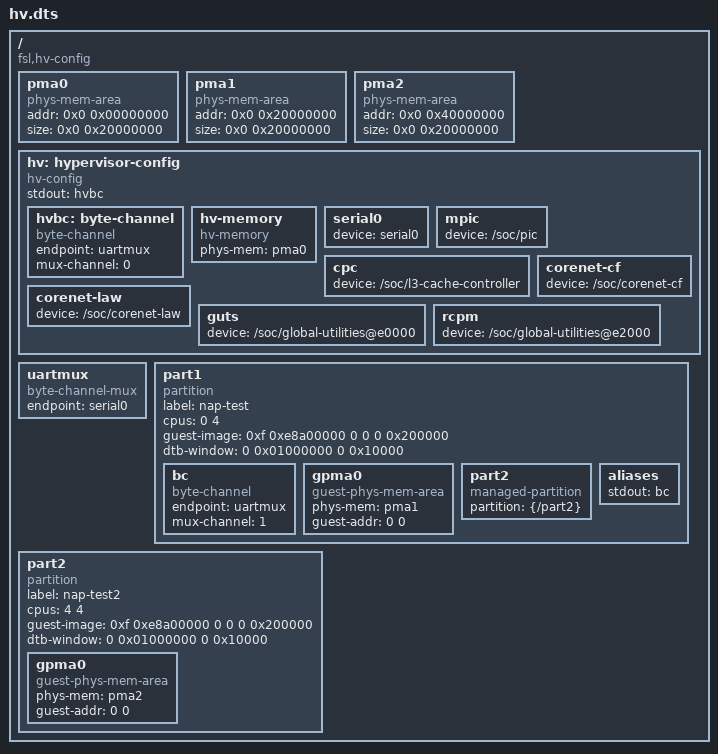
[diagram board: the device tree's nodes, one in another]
/*
 * Copyright (C) 2010 Freescale Semiconductor, Inc.
 *
 * Redistribution and use in source and binary forms, with or without
 * modification, are permitted provided that the following conditions
 * are met:
 * 1. Redistributions of source code must retain the above copyright
 *    notice, this list of conditions and the following disclaimer.
 * 2. Redistributions in binary form must reproduce the above copyright
 *    notice, this list of conditions and the following disclaimer in the
 *    documentation and/or other materials provided with the distribution.
 *
 * THIS SOFTWARE IS PROVIDED BY THE AUTHOR "AS IS" AND ANY EXPRESS OR
 * IMPLIED WARRANTIES, INCLUDING, BUT NOT LIMITED TO, THE IMPLIED WARRANTIES
 * OF MERCHANTABILITY AND FITNESS FOR A PARTICULAR PURPOSE ARE DISCLAIMED.  IN
 * NO EVENT SHALL THE AUTHOR BE LIABLE FOR ANY DIRECT, INDIRECT, INCIDENTAL,
 * SPECIAL, EXEMPLARY, OR CONSEQUENTIAL DAMAGES (INCLUDING, BUT NOT LIMITED
 * TO, PROCUREMENT OF SUBSTITUTE GOODS OR SERVICES; LOSS OF USE, DATA, OR
 * PROFITS; OR BUSINESS INTERRUPTION) HOWEVER CAUSED AND ON ANY THEORY OF
 * LIABILITY, WHETHER IN CONTRACT, STRICT LIABILITY, OR TORT (INCLUDING
 * NEGLIGENCE OR OTHERWISE) ARISING IN ANY WAY OUT OF THE USE OF THIS
 * SOFTWARE, EVEN IF ADVISED OF THE POSSIBILITY OF SUCH DAMAGE.
 */

/dts-v1/;

/ {
	compatible = "fsl,hv-config";

	// =====================================================
	// Physical Memory Areas
	// =====================================================
	pma0:pma0 {
		compatible = "phys-mem-area";
		addr = <0x0 0x00000000>;
		size = <0x0 0x20000000>;  // 512MB
	};

	pma1:pma1 {
		compatible = "phys-mem-area";
		addr = <0x0 0x20000000>;
		size = <0x0 0x20000000>;  // 512MB
	};

	pma2:pma2 {
		compatible = "phys-mem-area";
		addr = <0x0 0x40000000>;
		size = <0x0 0x20000000>;  // 512MB
	};

	// =====================================================
	// Hypervisor Config
	// =====================================================
	hv:hypervisor-config {
		compatible = "hv-config";
		stdout = <&hvbc>;

		hvbc: byte-channel {
			compatible = "byte-channel";
			endpoint = <&uartmux>;
			mux-channel = <0>;
		};

		hv-memory {
			compatible = "hv-memory";
			phys-mem = <&pma0>;
		};

		serial0:serial0 {
			device = "serial0";
		};

		mpic {
			device = "/soc/pic";
		};

		cpc {
			device = "/soc/l3-cache-controller";
		};

		corenet-law {
			device = "/soc/corenet-law";
		};

		corenet-cf {
			device = "/soc/corenet-cf";
		};

		guts {
			device = "/soc/global-utilities@e0000";
		};

		rcpm {
			device = "/soc/global-utilities@e2000";
		};
	};

	uartmux: uartmux {
		compatible = "byte-channel-mux";
		endpoint = <&serial0>;
	};

	// =====================================================
	// Partition 1
	// =====================================================
	part1 {
		compatible = "partition";
		label = "nap-test";
		cpus = <0 4>;
		guest-image = <0xf 0xe8a00000 0 0 0 0x200000>;
		dtb-window = <0 0x01000000 0 0x10000>;

		bc: bc {
			compatible = "byte-channel";
			endpoint = <&uartmux>;
			mux-channel = <1>;
		};

		gpma0 {
			compatible = "guest-phys-mem-area";
			phys-mem = <&pma1>;
			guest-addr = <0 0>;
		};

		part2 {
			compatible = "managed-partition";
			partition = <&{/part2}>;
		};

		aliases {
			stdout = <&bc>;
		};
	};

	// =====================================================
	// Partition 2
	// =====================================================
	part2 {
		compatible = "partition";
		label = "nap-test2";
		cpus = <4 4>;
		guest-image = <0xf 0xe8a00000 0 0 0 0x200000>;
		dtb-window = <0 0x01000000 0 0x10000>;

		gpma0 {
			compatible = "guest-phys-mem-area";
			phys-mem = <&pma2>;
			guest-addr = <0 0>;
		};
	};
};
